# ATA5787 device description
Architecture: AVR8; Family: megaAVR
Registers are 8-bit, access not given, no defined reset value unless marked. A register's access mark holds for its fields unless they carry their own. Offsets are from the block's base; [hi:lo] are bit positions.

## OCCOUNT
Instances: OCCOUNT 0x00
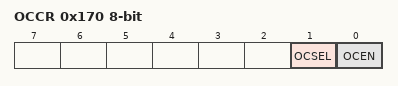
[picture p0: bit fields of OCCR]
0x170 OCCR — Oscillator Calibration Counter Configuration Register
  [1] OCSEL — Oscillator Calibration Select Target
  [0] OCEN — Oscillator Calibration Counter Enable
0x171 OCCNT — Oscillator Calibration Counter Value
0x172 OCGATE — Oscillator Calibration Counter Gate

## PORTB
Instances: PORTB 0x00
0x25 PINB — Port B Input Pins
0x26 DDRB — Port B Data Direction
0x27 PORTB — Port B Data Register

## PORTC
Instances: PORTC 0x00
0x28 PINC bits used 5:0 — Port C Input Pins
0x29 DDRC bits used 5:0 — Port C Data Direction
0x2A PORTC bits used 5:0 — Port C Data Register

## PORTS
Instances: PORTS 0x00
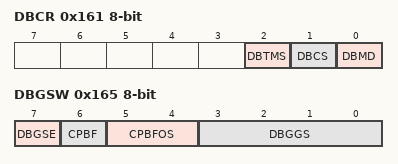
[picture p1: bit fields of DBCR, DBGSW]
0x161 DBCR — Debounce Control Register
  [2] DBTMS — Debounce Timer Mask Select
  [1] DBCS — Debounce Clock Select
  [0] DBMD — Debounce Mode
0x162 DBTC — Debounce Timer Compare
0x163 DBENB — Debounce Enable Port B
0x164 DBENC bits used 5:0 — Debounce Enable Port C
0x165 DBGSW — Debug Support Switch
  [7] DBGSE — Debug Support Switch Enable
  [6] CPBF — CPU Busy Flag
  [5:4] CPBFOS — CPU Busy Flag Output Select
    0=NO_OUTPUT; 1=PB0; 2=PB4; 3=PC1
  [3:0] DBGGS — Debug Support Group Select

## RSSIB
Instances: RSSIB 0x00
0x15C RSSAV — RSSI Average Value
0x15D RSSPK — RSSI Peak Value
0x15E RSSL — RSSI Low Threshold
0x15F RSSH — RSSI High Threshold
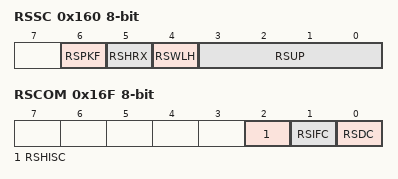
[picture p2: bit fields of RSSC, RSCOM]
0x160 RSSC — RSSI Configuration Register
  [6] RSPKF — RSSI Peak Values to SFIFO
  [5] RSHRX — RSSI High Band Reception
  [4] RSWLH — RSSI Within Low and High Limits
  [3:0] RSUP — RSSI Update Period
0x16B RSHSG — RSSI LNA High Sensitivity Gain
0x16C RSIFG — RSSI IF Amplifier Gain
0x16D RSLDV — RSSI Low Band Damping Value
0x16E RSHDV — RSSI High Band Damping Value
0x16F RSCOM — RSSI Compensation Register
  [2] RSHISC — RSSI LNA High Sensitivity Compensation
  [1] RSIFC — RSSI IF Amplifier Compensation
  [0] RSDC — RSSI Damping Compensation

## RXBUF
Instances: RXBUF 0x00
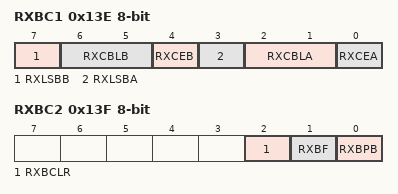
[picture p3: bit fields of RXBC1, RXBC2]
0x13E RXBC1 — Rx Buffer Configuration 1
  [7] RXLSBB — Receive Data LSB-First Path B
  [6:5] RXCBLB — Receive CRC Bit Length Path B
    0=CRC_4_BIT; 1=CRC_8_BIT; 2=CRC_16_BIT
  [4] RXCEB — RX CRC Enable data path B
  [3] RXLSBA — Receive Data LSB-First Path A
  [2:1] RXCBLA — Receive CRC Bit Length Path A
    0=CRC_4_BIT; 1=CRC_8_BIT; 2=CRC_16_BIT
  [0] RXCEA — RX CRC Enable data path A
0x13F RXBC2 — Rx Buffer Configuration 2
  [2] RXBCLR — RX Buffer Clear
  [1] RXBF — RX Buffer Finish
  [0] RXBPB — RX Buffer Path Select
0x140 RXTLLB — Rx Telegram Length Low Byte Path B
0x141 RXTLHB bits used 3:0 — Rx Telegram Length High Byte Path B
0x142 RXCRLB — Rx CRC Result Low Byte Path B
0x143 RXCRHB — Rx CRC Result High Byte Path B
0x144 RXCSBB — Rx CRC Skip Bit Number Path B
0x145 RXCILB — Rx CRC Init Value Low Byte Path B
0x146 RXCIHB — Rx CRC Init Value High Byte Path B
0x147 RXCPLB — Rx CRC Polynomial Low Byte Path B
0x148 RXCPHB — Rx CRC Polynomial High Byte Path B
0x149 RXDSB — Receive Data Shift Register Path B
0x14A RXTLLA — Rx Telegram Length Low Byte Path A
0x14B RXTLHA bits used 3:0 — Rx Telegram Length High Byte Path A
0x14C RXCRLA — Rx CRC Result Low Byte Path A
0x14D RXCRHA — Rx CRC Result High Byte Path A
0x14E RXCSBA — Rx CRC Skip Bit Number Path A
0x14F RXCILA — Rx CRC Init Value Low Byte Path A
0x150 RXCIHA — Rx CRC Init Value High Byte Path A
0x151 RXCPLA — Rx CRC Polynomial Low Byte Path A
0x152 RXCPHA — Rx CRC Polynomial High Byte Path A
0x153 RXDSA — Receive Data Shift Register Path A

## SFIFO
Instances: SFIFO 0x00
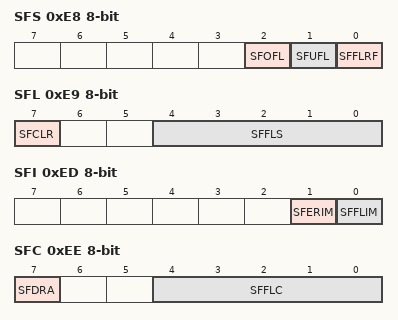
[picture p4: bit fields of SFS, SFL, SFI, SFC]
0xE8 SFS — Support FIFO Status
  [2] SFOFL — Support FIFO Overflow Flag
  [1] SFUFL — Support FIFO Underflow Flag
  [0] SFFLRF — Support FIFO Fill Level Reached Status Flag
0xE9 SFL — Support FIFO Fill Level
  [7] SFCLR — Support FIFO Clear
  [4:0] SFFLS — Support FIFO Fill Level Status
0xEA SFWP bits used 4:0 — Support FIFO Write Pointer
0xEB SFRP bits used 4:0 — Support FIFO Read Pointer
0xEC SFD — Support FIFO Data
0xED SFI — Support FIFO Interrupt Mask
  [1] SFERIM — Support FIFO Error Interrupt Mask
  [0] SFFLIM — Support FIFO Fill Level Interrupt Mask
0xEE SFC — Support FIFO Configuration
  [7] SFDRA — Support FIFO Direct Read Access Operational Mode
  [4:0] SFFLC — Support FIFO Fill Level Configuration
